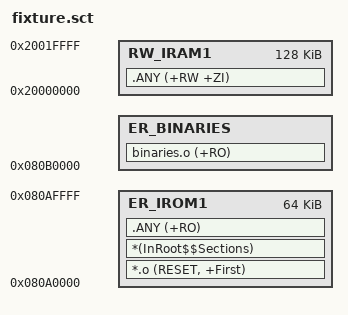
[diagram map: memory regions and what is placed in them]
; *************************************************************
; *** Scatter-Loading Description File generated by uVision ***
; *************************************************************

LR_IROM1 0x080A0000 0x00060000  {    ; load region size_region
  ; 64KB for program leaves the rest for resources
  ER_IROM1 0x080A0000 0x00010000  {  ; load address = execution address
   *.o (RESET, +First)
   *(InRoot$$Sections)
   .ANY (+RO)
  }
 
  RW_IRAM1 0x20000000 0x00020000  {  ; RW data
   .ANY (+RW +ZI)
  }
  
  ; Put all the resources at the end of flash
  ; If you get a weird linker error on this section, add "--datacompressor off" to the Linker options
  ; It turns out Keil's linker can't compute the length of its own compressed sections!
  ER_BINARIES 0x080B0000 ALIGN 0x10000 {
    binaries.o (+RO)
  }
}

